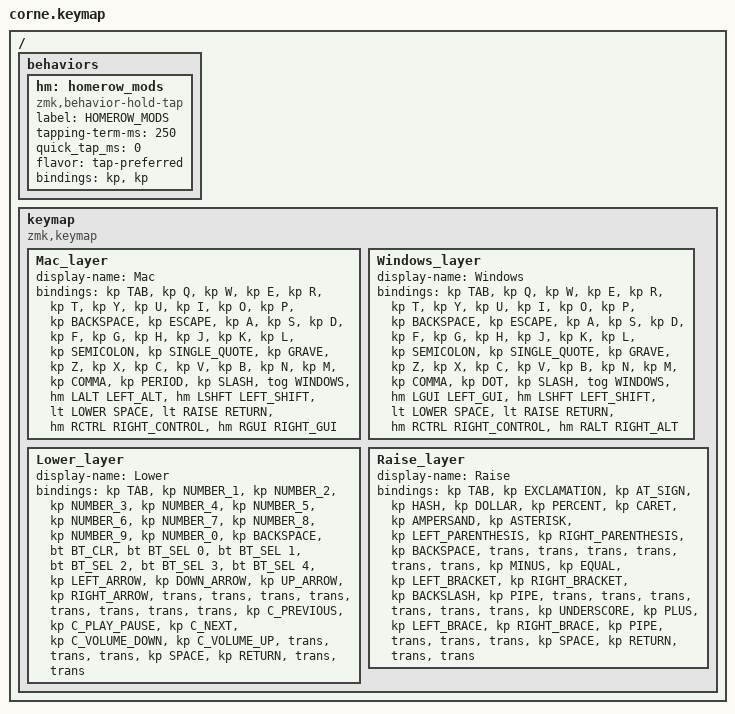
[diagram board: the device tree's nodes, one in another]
#include <behaviors.dtsi>
#include <dt-bindings/zmk/keys.h>
#include <dt-bindings/zmk/bt.h>

#define MAC 0
#define WINDOWS 1
#define LOWER 2
#define RAISE 3

/ {
  behaviors {
    hm: homerow_mods {
      compatible = "zmk,behavior-hold-tap";
      label = "HOMEROW_MODS";
      #binding-cells = <2>;
      tapping-term-ms = <250>;
      quick_tap_ms = <0>;
      flavor = "tap-preferred";
      bindings = <&kp>, <&kp>;
    };
  };
  keymap {
    compatible = "zmk,keymap";

    Mac_layer {
      display-name = "Mac";
      bindings = <
        &kp TAB &kp Q &kp W &kp E &kp R &kp T &kp Y &kp U &kp I &kp O &kp P &kp BACKSPACE &kp ESCAPE &kp A &kp S &kp D &kp F &kp G &kp H &kp J &kp K &kp L &kp SEMICOLON &kp SINGLE_QUOTE &kp GRAVE &kp Z &kp X &kp C &kp V &kp B &kp N &kp M &kp COMMA &kp PERIOD &kp SLASH &tog WINDOWS &hm LALT LEFT_ALT &hm LSHFT LEFT_SHIFT &lt LOWER SPACE &lt RAISE RETURN &hm RCTRL RIGHT_CONTROL &hm RGUI RIGHT_GUI
      >;
    };

    Windows_layer {
      display-name = "Windows";
      bindings = <
        &kp TAB &kp Q &kp W &kp E &kp R &kp T &kp Y &kp U &kp I &kp O &kp P &kp BACKSPACE &kp ESCAPE &kp A &kp S &kp D &kp F &kp G &kp H &kp J &kp K &kp L &kp SEMICOLON &kp SINGLE_QUOTE &kp GRAVE &kp Z &kp X &kp C &kp V &kp B &kp N &kp M &kp COMMA &kp DOT &kp SLASH &tog WINDOWS &hm LGUI LEFT_GUI &hm LSHFT LEFT_SHIFT &lt LOWER SPACE &lt RAISE RETURN &hm RCTRL RIGHT_CONTROL &hm RALT RIGHT_ALT 
      >;
    };

    Lower_layer {
      display-name = "Lower";
      bindings = <
        &kp TAB &kp NUMBER_1 &kp NUMBER_2 &kp NUMBER_3 &kp NUMBER_4 &kp NUMBER_5 &kp NUMBER_6 &kp NUMBER_7 &kp NUMBER_8 &kp NUMBER_9 &kp NUMBER_0 &kp BACKSPACE &bt BT_CLR &bt BT_SEL 0 &bt BT_SEL 1 &bt BT_SEL 2 &bt BT_SEL 3 &bt BT_SEL 4 &kp LEFT_ARROW &kp DOWN_ARROW &kp UP_ARROW &kp RIGHT_ARROW &trans &trans &trans &trans &trans &trans &trans &trans &kp C_PREVIOUS &kp C_PLAY_PAUSE &kp C_NEXT &kp C_VOLUME_DOWN &kp C_VOLUME_UP &trans &trans &trans &kp SPACE &kp RETURN &trans &trans 
      >;
    };

    Raise_layer {
      display-name = "Raise";
      bindings = <
        &kp TAB &kp EXCLAMATION &kp AT_SIGN &kp HASH &kp DOLLAR &kp PERCENT &kp CARET &kp AMPERSAND &kp ASTERISK &kp LEFT_PARENTHESIS &kp RIGHT_PARENTHESIS &kp BACKSPACE &trans &trans &trans &trans &trans &trans &kp MINUS &kp EQUAL &kp LEFT_BRACKET &kp RIGHT_BRACKET &kp BACKSLASH &kp PIPE &trans &trans &trans &trans &trans &trans &kp UNDERSCORE &kp PLUS &kp LEFT_BRACE &kp RIGHT_BRACE &kp PIPE &trans &trans &trans &kp SPACE &kp RETURN &trans &trans 
      >;
    };
  };
};
